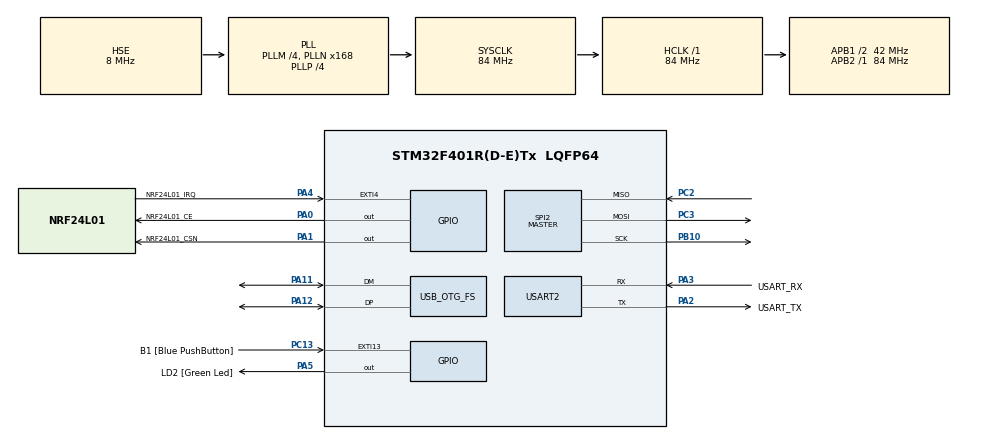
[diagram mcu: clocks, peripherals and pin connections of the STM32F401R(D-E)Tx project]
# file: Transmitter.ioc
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Mcu.Family=STM32F4
Mcu.Name=STM32F401R(D-E)Tx
Mcu.Package=LQFP64
NVIC.EXTI4_IRQn=true\:2\:0\:true\:false\:true\:true\:true\:true
NVIC.OTG_FS_IRQn=true\:5\:0\:true\:false\:true\:true\:true\:true
NVIC.PriorityGroup=NVIC_PRIORITYGROUP_4
NVIC.TIM2_IRQn=true\:2\:0\:true\:false\:true\:true\:true\:true
PA0-WKUP.GPIO_Label=NRF24L01_CE
PA0-WKUP.Signal=GPIO_Output
PA1.GPIO_Label=NRF24L01_CSN
PA1.PinState=GPIO_PIN_SET
PA1.Signal=GPIO_Output
PA11.Mode=Device_Only
PA11.Signal=USB_OTG_FS_DM
PA12.Mode=Device_Only
PA12.Signal=USB_OTG_FS_DP
PA13.GPIO_Label=TMS
PA13.Mode=Trace_Asynchronous_SW
PA13.Signal=SYS_JTMS-SWDIO
PA14.GPIO_Label=TCK
PA14.Mode=Trace_Asynchronous_SW
PA14.Signal=SYS_JTCK-SWCLK
PA2.GPIO_Label=USART_TX
PA2.GPIO_Mode=GPIO_MODE_AF_PP
PA2.GPIO_PuPd=GPIO_NOPULL
PA2.GPIO_Speed=GPIO_SPEED_FREQ_LOW
PA2.Mode=Asynchronous
PA2.Signal=USART2_TX
PA3.GPIO_Label=USART_RX
PA3.GPIO_Mode=GPIO_MODE_AF_PP
PA3.GPIO_PuPd=GPIO_NOPULL
PA3.GPIO_Speed=GPIO_SPEED_FREQ_LOW
PA3.Mode=Asynchronous
PA3.Signal=USART2_RX
PA4.GPIO_Label=NRF24L01_IRQ
PA4.GPIO_ModeDefaultEXTI=GPIO_MODE_IT_FALLING
PA4.Signal=GPXTI4
PA5.GPIO_Label=LD2 [Green Led]
PA5.GPIO_Mode=GPIO_MODE_OUTPUT_PP
PA5.GPIO_PuPd=GPIO_NOPULL
PA5.GPIO_Speed=GPIO_SPEED_FREQ_LOW
PA5.Signal=GPIO_Output
PB10.Mode=Full_Duplex_Master
PB10.Signal=SPI2_SCK
PB3.GPIO_Label=SWO
PB3.Mode=Trace_Asynchronous_SW
PB3.Signal=SYS_JTDO-SWO
PC13-ANTI_TAMP.GPIO_Label=B1 [Blue PushButton]
PC13-ANTI_TAMP.GPIO_ModeDefaultEXTI=GPIO_MODE_IT_FALLING
PC13-ANTI_TAMP.GPIO_PuPd=GPIO_NOPULL
PC13-ANTI_TAMP.Signal=GPXTI13
PC14-OSC32_IN.Mode=LSE-External-Oscillator
PC14-OSC32_IN.Signal=RCC_OSC32_IN
PC15-OSC32_OUT.Mode=LSE-External-Oscillator
PC15-OSC32_OUT.Signal=RCC_OSC32_OUT
PC2.Mode=Full_Duplex_Master
PC2.Signal=SPI2_MISO
PC3.Mode=Full_Duplex_Master
PC3.Signal=SPI2_MOSI
PH0\ -\ OSC_IN.Mode=HSE-External-Oscillator
PH0\ -\ OSC_IN.Signal=RCC_OSC_IN
PH1\ -\ OSC_OUT.Mode=HSE-External-Oscillator
PH1\ -\ OSC_OUT.Signal=RCC_OSC_OUT
ProjectManager.HeapSize=0x200
ProjectManager.StackSize=0x400
ProjectManager.TargetToolchain=CMake
RCC.48MHZClocksFreq_Value=48000000
RCC.AHBFreq_Value=84000000
RCC.APB1CLKDivider=RCC_HCLK_DIV2
RCC.APB1Freq_Value=42000000
RCC.APB1TimFreq_Value=84000000
RCC.APB2Freq_Value=84000000
RCC.APB2TimFreq_Value=84000000
RCC.CortexFreq_Value=84000000
RCC.HCLKFreq_Value=84000000
RCC.HSE_VALUE=8000000
RCC.HSI_VALUE=16000000
RCC.PLLM=4
RCC.PLLN=168
RCC.PLLP=RCC_PLLP_DIV4
RCC.PLLQ=7
RCC.SYSCLKFreq_VALUE=84000000
RCC.SYSCLKSource=RCC_SYSCLKSOURCE_PLLCLK
RCC.VCOOutputFreq_Value=336000000
SPI2.BaudRatePrescaler=SPI_BAUDRATEPRESCALER_16
SPI2.Direction=SPI_DIRECTION_2LINES
SPI2.Mode=SPI_MODE_MASTER
SPI2.VirtualType=VM_MASTER
TIM2.Channel-Output\ Compare1\ No\ Output=TIM_CHANNEL_1
TIM2.Period=9999
TIM2.Prescaler=83
TIM5.Prescaler=83
USART2.VirtualMode=VM_ASYNC
USB_DEVICE.CLASS_NAME_FS=CDC
USB_DEVICE.VirtualMode-CDC_FS=Cdc
USB_DEVICE.VirtualModeFS=Cdc_FS
USB_OTG_FS.VirtualMode=Device_Only
VP_TIM2_VS_ClockSourceINT.Mode=Internal
VP_TIM2_VS_no_output1.Mode=Output Compare1 No Output
VP_TIM5_VS_ClockSourceINT.Mode=Internal
VP_USB_DEVICE_VS_USB_DEVICE_CDC_FS.Mode=CDC_FS
board=NUCLEO-F401RE

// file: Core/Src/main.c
/* USER CODE BEGIN Header */
/**
 ******************************************************************************
 * @file           : main.c
 * @brief          : Main program body
 ******************************************************************************
 * @attention
 *
 * Copyright (c) 2026 STMicroelectronics.
 * All rights reserved.
 *
 * This software is licensed under terms that can be found in the LICENSE file
 * in the root directory of this software component.
 * If no LICENSE file comes with this software, it is provided AS-IS.
 *
 ******************************************************************************
 */
/* USER CODE END Header */
#include "main.h"
#include "usb_device.h"

/* USER CODE BEGIN Includes */
#include <stdio.h>
#include "app.h"
/* USER CODE END Includes */

SPI_HandleTypeDef hspi2;

TIM_HandleTypeDef htim2;
TIM_HandleTypeDef htim5;

UART_HandleTypeDef huart2;

void SystemClock_Config(void);
static void MX_GPIO_Init(void);
static void MX_SPI2_Init(void);
static void MX_USART2_UART_Init(void);
static void MX_TIM2_Init(void);
static void MX_TIM5_Init(void);

/* USER CODE BEGIN 0 */

// void Init()
// {
//   Setup_Radio();
//   NRF24L01_OpenTxPipe(&hnrf, TX_ADDRESS);
//   NRF24L01_SetDynamicAck(&hnrf, true);
//   NRF24L01_SetAutoAck(&hnrf, 0, true);

//   const uint8_t          data[5]    = {0x11, 0x11, 0x11, 0x11, 0x11};
//   NRF24L01_StatusTypeDef status     = NRF24L01_Transmit(&hnrf, data, 5, 3000, false);
//   uint8_t                observe_tx = NRF24L01_ReadReg(&hnrf, NRF24L01_REG_OBSERVE_TX);
//   char                   msg[64];
//   int                    n = snprintf(msg, sizeof(msg), "status=%d observe_tx=0x%02X\n", status, observe_tx);
//   HAL_UART_Transmit(&huart2, (uint8_t *)msg, n, HAL_MAX_DELAY);
//   if (status == NRF24L01_OK)
//     HAL_GPIO_WritePin(LD2_GPIO_Port, LD2_Pin, GPIO_PIN_SET);

//   const char ready[] = "Ready!\n";
//   HAL_UART_Transmit(&huart2, (uint8_t *)ready, sizeof(ready) - 1, HAL_MAX_DELAY);
// }
/* USER CODE END 0 */

int main(void)
{

  /* MCU Configuration--------------------------------------------------------*/

  /* Reset of all peripherals, Initializes the Flash interface and the Systick. */
  HAL_Init();

  /* Configure the system clock */
  SystemClock_Config();

  /* Initialize all configured peripherals */
  MX_GPIO_Init();
  MX_SPI2_Init();
  MX_USART2_UART_Init();
  MX_USB_DEVICE_Init();
  MX_TIM2_Init();
  MX_TIM5_Init();

  /* Infinite loop */
  /* USER CODE BEGIN WHILE */
  App_Init();
  while (1)
  {
    App_Loop();
    /* USER CODE END WHILE */

  }
}

void SystemClock_Config(void)
{
  RCC_OscInitTypeDef RCC_OscInitStruct = {0};
  RCC_ClkInitTypeDef RCC_ClkInitStruct = {0};

  /** Configure the main internal regulator output voltage
  */
  __HAL_RCC_PWR_CLK_ENABLE();
  __HAL_PWR_VOLTAGESCALING_CONFIG(PWR_REGULATOR_VOLTAGE_SCALE2);

  /** Initializes the RCC Oscillators according to the specified parameters
  * in the RCC_OscInitTypeDef structure.
  */
  RCC_OscInitStruct.OscillatorType = RCC_OSCILLATORTYPE_HSE;
  RCC_OscInitStruct.HSEState = RCC_HSE_ON;
  RCC_OscInitStruct.PLL.PLLState = RCC_PLL_ON;
  RCC_OscInitStruct.PLL.PLLSource = RCC_PLLSOURCE_HSE;
  RCC_OscInitStruct.PLL.PLLM = 4;
  RCC_OscInitStruct.PLL.PLLN = 168;
  RCC_OscInitStruct.PLL.PLLP = RCC_PLLP_DIV4;
  RCC_OscInitStruct.PLL.PLLQ = 7;
  if (HAL_RCC_OscConfig(&RCC_OscInitStruct) != HAL_OK)
  {
    Error_Handler();
  }

  /** Initializes the CPU, AHB and APB buses clocks
  */
  RCC_ClkInitStruct.ClockType = RCC_CLOCKTYPE_HCLK|RCC_CLOCKTYPE_SYSCLK
                              |RCC_CLOCKTYPE_PCLK1|RCC_CLOCKTYPE_PCLK2;
  RCC_ClkInitStruct.SYSCLKSource = RCC_SYSCLKSOURCE_PLLCLK;
  RCC_ClkInitStruct.AHBCLKDivider = RCC_SYSCLK_DIV1;
  RCC_ClkInitStruct.APB1CLKDivider = RCC_HCLK_DIV2;
  RCC_ClkInitStruct.APB2CLKDivider = RCC_HCLK_DIV1;

  if (HAL_RCC_ClockConfig(&RCC_ClkInitStruct, FLASH_LATENCY_2) != HAL_OK)
  {
    Error_Handler();
  }
}

static void MX_SPI2_Init(void)
{

  /* SPI2 parameter configuration*/
  hspi2.Instance = SPI2;
  hspi2.Init.Mode = SPI_MODE_MASTER;
  hspi2.Init.Direction = SPI_DIRECTION_2LINES;
  hspi2.Init.DataSize = SPI_DATASIZE_8BIT;
  hspi2.Init.CLKPolarity = SPI_POLARITY_LOW;
  hspi2.Init.CLKPhase = SPI_PHASE_1EDGE;
  hspi2.Init.NSS = SPI_NSS_SOFT;
  hspi2.Init.BaudRatePrescaler = SPI_BAUDRATEPRESCALER_16;
  hspi2.Init.FirstBit = SPI_FIRSTBIT_MSB;
  hspi2.Init.TIMode = SPI_TIMODE_DISABLE;
  hspi2.Init.CRCCalculation = SPI_CRCCALCULATION_DISABLE;
  hspi2.Init.CRCPolynomial = 10;
  if (HAL_SPI_Init(&hspi2) != HAL_OK)
  {
    Error_Handler();
  }

}

static void MX_TIM2_Init(void)
{

  TIM_ClockConfigTypeDef sClockSourceConfig = {0};
  TIM_MasterConfigTypeDef sMasterConfig = {0};
  TIM_OC_InitTypeDef sConfigOC = {0};

  htim2.Instance = TIM2;
  htim2.Init.Prescaler = 83;
  htim2.Init.CounterMode = TIM_COUNTERMODE_UP;
  htim2.Init.Period = 9999;
  htim2.Init.ClockDivision = TIM_CLOCKDIVISION_DIV1;
  htim2.Init.AutoReloadPreload = TIM_AUTORELOAD_PRELOAD_DISABLE;
  if (HAL_TIM_Base_Init(&htim2) != HAL_OK)
  {
    Error_Handler();
  }
  sClockSourceConfig.ClockSource = TIM_CLOCKSOURCE_INTERNAL;
  if (HAL_TIM_ConfigClockSource(&htim2, &sClockSourceConfig) != HAL_OK)
  {
    Error_Handler();
  }
  if (HAL_TIM_OC_Init(&htim2) != HAL_OK)
  {
    Error_Handler();
  }
  sMasterConfig.MasterOutputTrigger = TIM_TRGO_RESET;
  sMasterConfig.MasterSlaveMode = TIM_MASTERSLAVEMODE_DISABLE;
  if (HAL_TIMEx_MasterConfigSynchronization(&htim2, &sMasterConfig) != HAL_OK)
  {
    Error_Handler();
  }
  sConfigOC.OCMode = TIM_OCMODE_TIMING;
  sConfigOC.Pulse = 0;
  sConfigOC.OCPolarity = TIM_OCPOLARITY_HIGH;
  sConfigOC.OCFastMode = TIM_OCFAST_DISABLE;
  if (HAL_TIM_OC_ConfigChannel(&htim2, &sConfigOC, TIM_CHANNEL_1) != HAL_OK)
  {
    Error_Handler();
  }

}

static void MX_TIM5_Init(void)
{

  TIM_ClockConfigTypeDef sClockSourceConfig = {0};
  TIM_MasterConfigTypeDef sMasterConfig = {0};

  htim5.Instance = TIM5;
  htim5.Init.Prescaler = 83;
  htim5.Init.CounterMode = TIM_COUNTERMODE_UP;
  htim5.Init.Period = 4294967295;
  htim5.Init.ClockDivision = TIM_CLOCKDIVISION_DIV1;
  htim5.Init.AutoReloadPreload = TIM_AUTORELOAD_PRELOAD_DISABLE;
  if (HAL_TIM_Base_Init(&htim5) != HAL_OK)
  {
    Error_Handler();
  }
  sClockSourceConfig.ClockSource = TIM_CLOCKSOURCE_INTERNAL;
  if (HAL_TIM_ConfigClockSource(&htim5, &sClockSourceConfig) != HAL_OK)
  {
    Error_Handler();
  }
  sMasterConfig.MasterOutputTrigger = TIM_TRGO_RESET;
  sMasterConfig.MasterSlaveMode = TIM_MASTERSLAVEMODE_DISABLE;
  if (HAL_TIMEx_MasterConfigSynchronization(&htim5, &sMasterConfig) != HAL_OK)
  {
    Error_Handler();
  }

}

static void MX_USART2_UART_Init(void)
{

  huart2.Instance = USART2;
  huart2.Init.BaudRate = 115200;
  huart2.Init.WordLength = UART_WORDLENGTH_8B;
  huart2.Init.StopBits = UART_STOPBITS_1;
  huart2.Init.Parity = UART_PARITY_NONE;
  huart2.Init.Mode = UART_MODE_TX_RX;
  huart2.Init.HwFlowCtl = UART_HWCONTROL_NONE;
  huart2.Init.OverSampling = UART_OVERSAMPLING_16;
  if (HAL_UART_Init(&huart2) != HAL_OK)
  {
    Error_Handler();
  }

}

static void MX_GPIO_Init(void)
{
  GPIO_InitTypeDef GPIO_InitStruct = {0};

  /* GPIO Ports Clock Enable */
  __HAL_RCC_GPIOC_CLK_ENABLE();
  __HAL_RCC_GPIOH_CLK_ENABLE();
  __HAL_RCC_GPIOA_CLK_ENABLE();
  __HAL_RCC_GPIOB_CLK_ENABLE();

  /*Configure GPIO pin Output Level */
  HAL_GPIO_WritePin(GPIOA, NRF24L01_CE_Pin|LD2_Pin, GPIO_PIN_RESET);

  /*Configure GPIO pin Output Level */
  HAL_GPIO_WritePin(NRF24L01_CSN_GPIO_Port, NRF24L01_CSN_Pin, GPIO_PIN_SET);

  /*Configure GPIO pin : B1_Pin */
  GPIO_InitStruct.Pin = B1_Pin;
  GPIO_InitStruct.Mode = GPIO_MODE_IT_FALLING;
  GPIO_InitStruct.Pull = GPIO_NOPULL;
  HAL_GPIO_Init(B1_GPIO_Port, &GPIO_InitStruct);

  /*Configure GPIO pins : NRF24L01_CE_Pin NRF24L01_CSN_Pin LD2_Pin */
  GPIO_InitStruct.Pin = NRF24L01_CE_Pin|NRF24L01_CSN_Pin|LD2_Pin;
  GPIO_InitStruct.Mode = GPIO_MODE_OUTPUT_PP;
  GPIO_InitStruct.Pull = GPIO_NOPULL;
  GPIO_InitStruct.Speed = GPIO_SPEED_FREQ_LOW;
  HAL_GPIO_Init(GPIOA, &GPIO_InitStruct);

  /*Configure GPIO pin : NRF24L01_IRQ_Pin */
  GPIO_InitStruct.Pin = NRF24L01_IRQ_Pin;
  GPIO_InitStruct.Mode = GPIO_MODE_IT_FALLING;
  GPIO_InitStruct.Pull = GPIO_NOPULL;
  HAL_GPIO_Init(NRF24L01_IRQ_GPIO_Port, &GPIO_InitStruct);

  /* EXTI interrupt init*/
  HAL_NVIC_SetPriority(EXTI4_IRQn, 2, 0);
  HAL_NVIC_EnableIRQ(EXTI4_IRQn);

}

void Error_Handler(void)
{
  __disable_irq();
  while (1)
  {
  }
}
